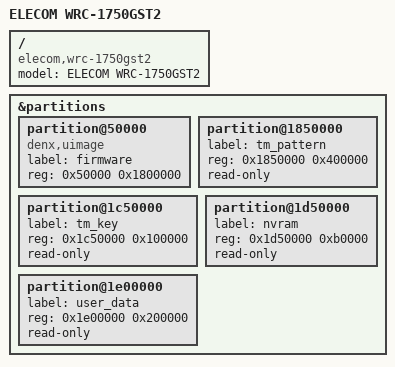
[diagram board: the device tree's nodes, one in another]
// SPDX-License-Identifier: GPL-2.0-or-later OR MIT

#include "mt7621_elecom_wrc-gs-2pci.dtsi"

/ {
	compatible = "elecom,wrc-1750gst2", "mediatek,mt7621-soc";
	model = "ELECOM WRC-1750GST2";
};

&partitions {
	partition@50000 {
		compatible = "denx,uimage";
		label = "firmware";
		reg = <0x50000 0x1800000>;
	};

	partition@1850000 {
		label = "tm_pattern";
		reg = <0x1850000 0x400000>;
		read-only;
	};

	partition@1c50000 {
		label = "tm_key";
		reg = <0x1c50000 0x100000>;
		read-only;
	};

	partition@1d50000 {
		label = "nvram";
		reg = <0x1d50000 0xb0000>;
		read-only;
	};

	partition@1e00000 {
		label = "user_data";
		reg = <0x1e00000 0x200000>;
		read-only;
	};
};
